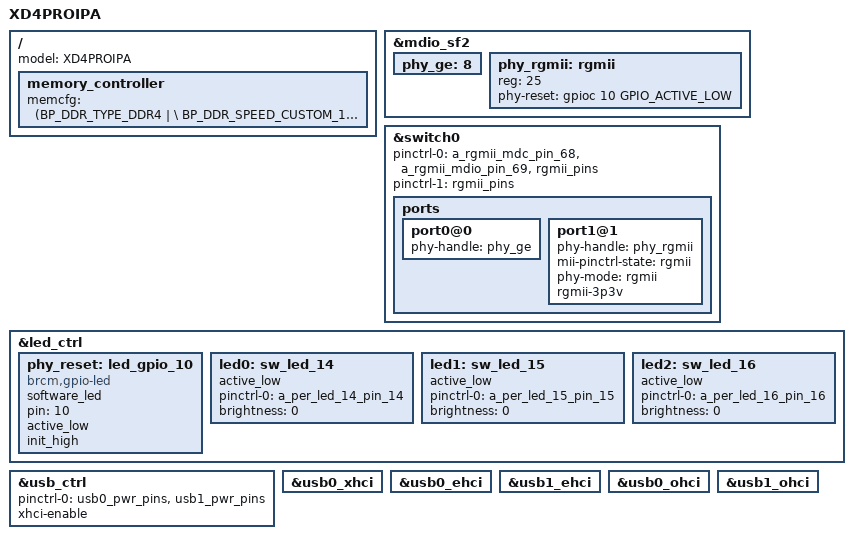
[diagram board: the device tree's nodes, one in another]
#include "6756.dtsi"

/ {
	model="XD4PROIPA";

	memory_controller {
		memcfg = <(BP_DDR_TYPE_DDR4       | \
			/* CUSTOM speed 1026MHz */
			BP_DDR_SPEED_CUSTOM_1         | \
			BP_DDR_TOTAL_SIZE_512MB       | \
			BP_DDR_DEVICE_WIDTH_16        | \
			BP_DDR_TOTAL_WIDTH_16BIT      | \
			BP_DDR_TEMP_EXTENDED_ASR      | \
			BP_DDR_6756_DEFAULT)>;
	};
};


&mdio_sf2 {
	phy_ge:8 {
		status = "okay";
	};
	phy_rgmii:rgmii {
		reg = <25>;
        phy-reset = <&gpioc 10 GPIO_ACTIVE_LOW>;
		status = "okay";
	};
};

&switch0 {
    pinctrl-names = "default", "rgmii";
    pinctrl-0 = <&a_rgmii_mdc_pin_68 &a_rgmii_mdio_pin_69 &rgmii_pins>;
    pinctrl-1 = <&rgmii_pins>;
 
	ports {
		port0@0 {
            phy-handle = <&phy_ge>;
			status = "okay";
		};
		port1@1 {
            phy-handle = <&phy_rgmii>;
			mii-pinctrl-state = "rgmii";
			phy-mode = "rgmii";
			rgmii-3p3v;
			status = "okay";
		};		
	};
};

&led_ctrl {
    status="okay";

	/* WAR:50212 PHY Reset */
    phy_reset:led_gpio_10 {
		compatible = "brcm,gpio-led";
		software_led;
		pin = <10>;
        active_low;
		init_high;
	};
	led0:sw_led_14 {
		active_low;
		pinctrl-0=<&a_per_led_14_pin_14>;
		status = "okay";
		brightness = <0>;
	};
	led1:sw_led_15 {
		active_low;
		pinctrl-0=<&a_per_led_15_pin_15>;
		status = "okay";
		brightness = <0>;
	};
	led2:sw_led_16 {
		active_low;
		pinctrl-0=<&a_per_led_16_pin_16>;
		status = "okay";
		brightness = <0>;
	};
};

&usb_ctrl {
    pinctrl-names="default";
    pinctrl-0 = <&usb0_pwr_pins &usb1_pwr_pins>;
    status = "okay";
    xhci-enable;
};

&usb0_xhci {
    status = "okay";
};

&usb0_ehci {
    status = "okay";
};

&usb1_ehci {
    status = "okay";
};

&usb0_ohci {
    status = "okay";
};

&usb1_ohci {
    status = "okay";
};
